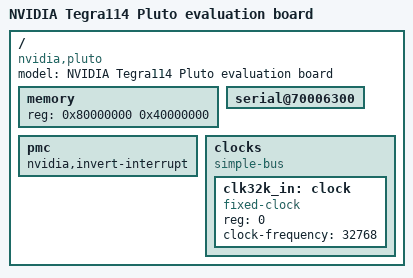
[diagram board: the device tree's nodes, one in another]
# 1 "arch/arm/boot/dts/tegra114-pluto.dts"
# 1 "<built-in>"
# 1 "<command-line>"
# 1 "arch/arm/boot/dts/tegra114-pluto.dts"
/dts-v1/;

/include/ "tegra114.dtsi"

/ {
 model = "NVIDIA Tegra114 Pluto evaluation board";
 compatible = "nvidia,pluto", "nvidia,tegra114";

 memory {
  reg = <0x80000000 0x40000000>;
 };

 serial@70006300 {
  status = "okay";
 };

 pmc {
  nvidia,invert-interrupt;
 };

 clocks {
  compatible = "simple-bus";
  #address-cells = <1>;
  #size-cells = <0>;

  clk32k_in: clock {
   compatible = "fixed-clock";
   reg=<0>;
   #clock-cells = <0>;
   clock-frequency = <32768>;
  };
 };
};
